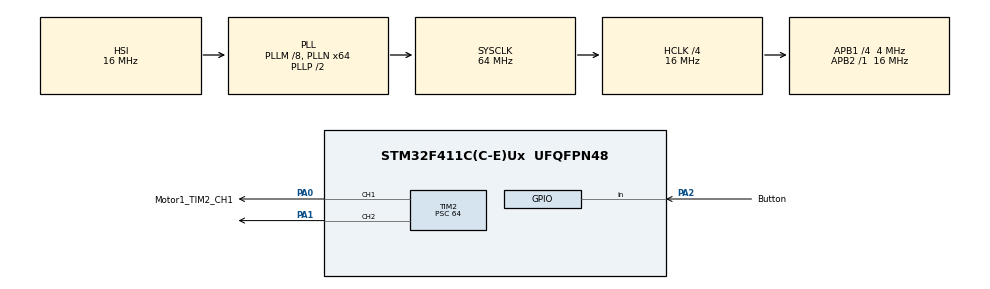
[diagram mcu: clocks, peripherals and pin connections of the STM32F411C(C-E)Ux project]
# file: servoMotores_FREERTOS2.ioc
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FREERTOS.Tasks01=gripperTask,26,128,StartGripperTask,Default,NULL,Dynamic,NULL,NULL;artTask,25,128,StartArtTask,Default,NULL,Dynamic,NULL,NULL;stopMotors,24,128,StopMotorMov,Default,NULL,Dynamic,NULL,NULL;receiveJetson,48,128,StartReceiveJetson,Default,NULL,Dynamic,NULL,NULL;emStop,32,128,StartEmStop,Default,NULL,Dynamic,NULL,NULL;checkButton,16,128,StartCheckButton,Default,NULL,Dynamic,NULL,NULL;transmitJetson,8,128,StartTransmitJEtson,Default,NULL,Dynamic,NULL,NULL
FREERTOS.configUSE_NEWLIB_REENTRANT=1
Mcu.Family=STM32F4
Mcu.Name=STM32F411C(C-E)Ux
Mcu.Package=UFQFPN48
NVIC.PriorityGroup=NVIC_PRIORITYGROUP_4
NVIC.TIM2_IRQn=true\:5\:0\:false\:false\:true\:true\:true\:true\:true
NVIC.TIM3_IRQn=true\:15\:0\:false\:false\:true\:false\:false\:true\:true
NVIC.TimeBase=TIM3_IRQn
NVIC.TimeBaseIP=TIM3
PA0-WKUP.GPIO_Label=Motor1_TIM2_CH1
PA0-WKUP.Signal=S_TIM2_CH1_ETR
PA1.Signal=S_TIM2_CH2
PA13.Mode=Serial_Wire
PA13.Signal=SYS_JTMS-SWDIO
PA14.Mode=Serial_Wire
PA14.Signal=SYS_JTCK-SWCLK
PA2.GPIO_Label=Button
PA2.Signal=GPIO_Input
PC14-OSC32_IN.Mode=LSE-External-Oscillator
PC14-OSC32_IN.Signal=RCC_OSC32_IN
PC15-OSC32_OUT.Mode=LSE-External-Oscillator
PC15-OSC32_OUT.Signal=RCC_OSC32_OUT
PH0\ -\ OSC_IN.Mode=HSE-External-Oscillator
PH0\ -\ OSC_IN.Signal=RCC_OSC_IN
PH1\ -\ OSC_OUT.Mode=HSE-External-Oscillator
PH1\ -\ OSC_OUT.Signal=RCC_OSC_OUT
ProjectManager.HeapSize=0x200
ProjectManager.StackSize=0x400
ProjectManager.TargetToolchain=STM32CubeIDE
RCC.48MHZClocksFreq_Value=32000000
RCC.AHBCLKDivider=RCC_SYSCLK_DIV4
RCC.AHBFreq_Value=16000000
RCC.APB1CLKDivider=RCC_HCLK_DIV4
RCC.APB1Freq_Value=4000000
RCC.APB1TimFreq_Value=8000000
RCC.APB2Freq_Value=16000000
RCC.APB2TimFreq_Value=16000000
RCC.CortexFreq_Value=16000000
RCC.HCLKFreq_Value=16000000
RCC.HSE_VALUE=25000000
RCC.HSI_VALUE=16000000
RCC.PLLM=8
RCC.PLLN=64
RCC.SYSCLKFreq_VALUE=64000000
RCC.SYSCLKSource=RCC_SYSCLKSOURCE_PLLCLK
RCC.VCOOutputFreq_Value=128000000
SH.S_TIM2_CH1_ETR.0=TIM2_CH1,PWM Generation1 CH1
SH.S_TIM2_CH2.0=TIM2_CH2,PWM Generation2 CH2
TIM2.Channel-PWM\ Generation1\ CH1=TIM_CHANNEL_1
TIM2.Channel-PWM\ Generation2\ CH2=TIM_CHANNEL_2
TIM2.Period=2499
TIM2.Prescaler=64
VP_FREERTOS_VS_CMSIS_V2.Mode=CMSIS_V2
VP_SYS_VS_tim3.Mode=TIM3
VP_TIM2_VS_ClockSourceINT.Mode=Internal
board=custom

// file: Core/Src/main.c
/* USER CODE BEGIN Header */
/**
  ******************************************************************************
  * @file           : main.c
  * @brief          : Main program body
  ******************************************************************************
  * @attention
  *
  * Copyright (c) 2023 STMicroelectronics.
  * All rights reserved.
  *
  * This software is licensed under terms that can be found in the LICENSE file
  * in the root directory of this software component.
  * If no LICENSE file comes with this software, it is provided AS-IS.
  *
  ******************************************************************************
  */
/* USER CODE END Header */
#include "main.h"
#include "cmsis_os.h"

TIM_HandleTypeDef htim2;

/* Definitions for gripperTask */
osThreadId_t gripperTaskHandle;
const osThreadAttr_t gripperTask_attributes = {
  .name = "gripperTask",
  .stack_size = 128 * 4,
  .priority = (osPriority_t) osPriorityNormal2,
};
/* Definitions for artTask */
osThreadId_t artTaskHandle;
const osThreadAttr_t artTask_attributes = {
  .name = "artTask",
  .stack_size = 128 * 4,
  .priority = (osPriority_t) osPriorityNormal1,
};
/* Definitions for stopMotors */
osThreadId_t stopMotorsHandle;
const osThreadAttr_t stopMotors_attributes = {
  .name = "stopMotors",
  .stack_size = 128 * 4,
  .priority = (osPriority_t) osPriorityNormal,
};
/* Definitions for receiveJetson */
osThreadId_t receiveJetsonHandle;
const osThreadAttr_t receiveJetson_attributes = {
  .name = "receiveJetson",
  .stack_size = 128 * 4,
  .priority = (osPriority_t) osPriorityRealtime,
};
/* Definitions for emStop */
osThreadId_t emStopHandle;
const osThreadAttr_t emStop_attributes = {
  .name = "emStop",
  .stack_size = 128 * 4,
  .priority = (osPriority_t) osPriorityAboveNormal,
};
/* Definitions for checkButton */
osThreadId_t checkButtonHandle;
const osThreadAttr_t checkButton_attributes = {
  .name = "checkButton",
  .stack_size = 128 * 4,
  .priority = (osPriority_t) osPriorityBelowNormal,
};
/* Definitions for transmitJetson */
osThreadId_t transmitJetsonHandle;
const osThreadAttr_t transmitJetson_attributes = {
  .name = "transmitJetson",
  .stack_size = 128 * 4,
  .priority = (osPriority_t) osPriorityLow,
};
/* USER CODE BEGIN PV */
int gripper = 0, art = 0;
int gripperOpen = 75, gripperClose = 127, artUp = 197, artDown = 83;
int comm[2];
int gripperFlag = 0, artFlag = 0, stopFlag = 0;
int gripperOK = 0, artOK = 0, stopOK = 0, objectHeld = 0;
int okFlags[4];
/* USER CODE END PV */

void SystemClock_Config(void);
static void MX_GPIO_Init(void);
static void MX_TIM2_Init(void);
void StartGripperTask(void *argument);
void StartArtTask(void *argument);
void StopMotorMov(void *argument);
void StartReceiveJetson(void *argument);
void StartEmStop(void *argument);
void StartCheckButton(void *argument);
void StartTransmitJEtson(void *argument);

/* USER CODE BEGIN PFP */
void read(void);
/* USER CODE END PFP */

int main(void)
{

  /* MCU Configuration--------------------------------------------------------*/

  /* Reset of all peripherals, Initializes the Flash interface and the Systick. */
  HAL_Init();

  /* Configure the system clock */
  SystemClock_Config();

  /* Initialize all configured peripherals */
  MX_GPIO_Init();
  MX_TIM2_Init();
  /* USER CODE BEGIN 2 */

  HAL_TIM_PWM_Start(&htim2,TIM_CHANNEL_1);
  HAL_TIM_PWM_Start(&htim2,TIM_CHANNEL_2);
  /* USER CODE END 2 */

  /* Init scheduler */
  osKernelInitialize();

  /* Create the thread(s) */
  /* creation of gripperTask */
  gripperTaskHandle = osThreadNew(StartGripperTask, NULL, &gripperTask_attributes);

  /* creation of artTask */
  artTaskHandle = osThreadNew(StartArtTask, NULL, &artTask_attributes);

  /* creation of stopMotors */
  stopMotorsHandle = osThreadNew(StopMotorMov, NULL, &stopMotors_attributes);

  /* creation of receiveJetson */
  receiveJetsonHandle = osThreadNew(StartReceiveJetson, NULL, &receiveJetson_attributes);

  /* creation of emStop */
  emStopHandle = osThreadNew(StartEmStop, NULL, &emStop_attributes);

  /* creation of checkButton */
  checkButtonHandle = osThreadNew(StartCheckButton, NULL, &checkButton_attributes);

  /* creation of transmitJetson */
  transmitJetsonHandle = osThreadNew(StartTransmitJEtson, NULL, &transmitJetson_attributes);

  /* Start scheduler */
  osKernelStart();
  /* We should never get here as control is now taken by the scheduler */
  /* Infinite loop */
  while (1)
  {

  }
}

void SystemClock_Config(void)
{
  RCC_OscInitTypeDef RCC_OscInitStruct = {0};
  RCC_ClkInitTypeDef RCC_ClkInitStruct = {0};

  /** Configure the main internal regulator output voltage
  */
  __HAL_RCC_PWR_CLK_ENABLE();
  __HAL_PWR_VOLTAGESCALING_CONFIG(PWR_REGULATOR_VOLTAGE_SCALE1);

  /** Initializes the RCC Oscillators according to the specified parameters
  * in the RCC_OscInitTypeDef structure.
  */
  RCC_OscInitStruct.OscillatorType = RCC_OSCILLATORTYPE_HSI;
  RCC_OscInitStruct.HSIState = RCC_HSI_ON;
  RCC_OscInitStruct.HSICalibrationValue = RCC_HSICALIBRATION_DEFAULT;
  RCC_OscInitStruct.PLL.PLLState = RCC_PLL_ON;
  RCC_OscInitStruct.PLL.PLLSource = RCC_PLLSOURCE_HSI;
  RCC_OscInitStruct.PLL.PLLM = 8;
  RCC_OscInitStruct.PLL.PLLN = 64;
  RCC_OscInitStruct.PLL.PLLP = RCC_PLLP_DIV2;
  RCC_OscInitStruct.PLL.PLLQ = 4;
  if (HAL_RCC_OscConfig(&RCC_OscInitStruct) != HAL_OK)
  {
    Error_Handler();
  }

  /** Initializes the CPU, AHB and APB buses clocks
  */
  RCC_ClkInitStruct.ClockType = RCC_CLOCKTYPE_HCLK|RCC_CLOCKTYPE_SYSCLK
                              |RCC_CLOCKTYPE_PCLK1|RCC_CLOCKTYPE_PCLK2;
  RCC_ClkInitStruct.SYSCLKSource = RCC_SYSCLKSOURCE_PLLCLK;
  RCC_ClkInitStruct.AHBCLKDivider = RCC_SYSCLK_DIV4;
  RCC_ClkInitStruct.APB1CLKDivider = RCC_HCLK_DIV4;
  RCC_ClkInitStruct.APB2CLKDivider = RCC_HCLK_DIV1;

  if (HAL_RCC_ClockConfig(&RCC_ClkInitStruct, FLASH_LATENCY_0) != HAL_OK)
  {
    Error_Handler();
  }
}

static void MX_TIM2_Init(void)
{

  TIM_ClockConfigTypeDef sClockSourceConfig = {0};
  TIM_MasterConfigTypeDef sMasterConfig = {0};
  TIM_OC_InitTypeDef sConfigOC = {0};

  htim2.Instance = TIM2;
  htim2.Init.Prescaler = 64;
  htim2.Init.CounterMode = TIM_COUNTERMODE_UP;
  htim2.Init.Period = 2499;
  htim2.Init.ClockDivision = TIM_CLOCKDIVISION_DIV1;
  htim2.Init.AutoReloadPreload = TIM_AUTORELOAD_PRELOAD_DISABLE;
  if (HAL_TIM_Base_Init(&htim2) != HAL_OK)
  {
    Error_Handler();
  }
  sClockSourceConfig.ClockSource = TIM_CLOCKSOURCE_INTERNAL;
  if (HAL_TIM_ConfigClockSource(&htim2, &sClockSourceConfig) != HAL_OK)
  {
    Error_Handler();
  }
  if (HAL_TIM_PWM_Init(&htim2) != HAL_OK)
  {
    Error_Handler();
  }
  sMasterConfig.MasterOutputTrigger = TIM_TRGO_RESET;
  sMasterConfig.MasterSlaveMode = TIM_MASTERSLAVEMODE_DISABLE;
  if (HAL_TIMEx_MasterConfigSynchronization(&htim2, &sMasterConfig) != HAL_OK)
  {
    Error_Handler();
  }
  sConfigOC.OCMode = TIM_OCMODE_PWM1;
  sConfigOC.Pulse = 0;
  sConfigOC.OCPolarity = TIM_OCPOLARITY_HIGH;
  sConfigOC.OCFastMode = TIM_OCFAST_DISABLE;
  if (HAL_TIM_PWM_ConfigChannel(&htim2, &sConfigOC, TIM_CHANNEL_1) != HAL_OK)
  {
    Error_Handler();
  }
  if (HAL_TIM_PWM_ConfigChannel(&htim2, &sConfigOC, TIM_CHANNEL_2) != HAL_OK)
  {
    Error_Handler();
  }
  HAL_TIM_MspPostInit(&htim2);

}

static void MX_GPIO_Init(void)
{
  GPIO_InitTypeDef GPIO_InitStruct = {0};

  /* GPIO Ports Clock Enable */
  __HAL_RCC_GPIOC_CLK_ENABLE();
  __HAL_RCC_GPIOH_CLK_ENABLE();
  __HAL_RCC_GPIOA_CLK_ENABLE();

  /*Configure GPIO pin : Button_Pin */
  GPIO_InitStruct.Pin = Button_Pin;
  GPIO_InitStruct.Mode = GPIO_MODE_INPUT;
  GPIO_InitStruct.Pull = GPIO_NOPULL;
  HAL_GPIO_Init(Button_GPIO_Port, &GPIO_InitStruct);

}

/* USER CODE BEGIN 4 */
void read() {
    comm[0] = 1;
    comm[1] = 2;
}
/* USER CODE END 4 */

void StartGripperTask(void *argument)
{
  /* USER CODE BEGIN 5 */
  /* Infinite loop */
  for(;;)
  {
	  if(gripperFlag == 1)
	  {
		  TIM2->CCR1 = gripperOpen;
		  osDelay(50);
		  gripperFlag = 0;
  		  gripperOK = 1;
	  }
	  else if (gripperFlag == 2)
	  {
		  TIM2->CCR1 = gripperClose;
		  osDelay(2000);
		  gripperFlag = 0;
  		  gripperOK = 1;
	  }
    osDelay(100);
  }
  /* USER CODE END 5 */
}

void StartArtTask(void *argument)
{
  /* USER CODE BEGIN StartArtTask */
  /* Infinite loop */
  for(;;)
  {
	  if(artFlag == 1)
	  	  {
	  		  TIM2->CCR2 = artUp;
	  		  osDelay(50);
	  		  artFlag = 0;
	  		  artOK = 1;
	  	  }
	 else if (artFlag == 2)
	  	  {
	  		  TIM2->CCR2 = artDown;
	  		  osDelay(50);
	  		  artFlag = 0;
	  		  artOK = 1;
	  	  }
	 osDelay(1);
  }
  /* USER CODE END StartArtTask */
}

void StopMotorMov(void *argument)
{
  for(;;)
  {
    osDelay(1);
  }
}

void StartReceiveJetson(void *argument)
{
  /* USER CODE BEGIN StartReceiveJetson */
  /* Infinite loop */
  for(;;)
  {
	 read();
	 switch (comm[0]){
	 	 case 1:
	 		 if (comm[1]==1)
				{
					gripperFlag = 1;
				}
			 else if (comm[1]==2)
				{
					gripperFlag = 2;
				}
			 else
				{
					gripperFlag = 0;
				}
			 break;
		 case 2:
			 if (comm[1]==1)
				{
					artFlag = 1;
				}
			 else if (comm[1]==2)
				{
					artFlag = 2;
				}
			 else
				{
					artFlag = 0;
				}
			 break;
		 case 3:
				stopFlag = 1;
				break;
		default:
				gripperFlag = 0;
				artFlag = 0;
				stopFlag = 0;
	            break;
		  }
	    osDelay(20000);
  }
  /* USER CODE END StartReceiveJetson */
}

void StartEmStop(void *argument)
{
  /* USER CODE BEGIN StartEmStop */
  /* Infinite loop */
  for(;;)
  {
	  if(stopFlag == 1){
		  gripperFlag = 0;
		  artFlag = 0;
		  stopFlag = 0;
	  }
    osDelay(1);
  }
  /* USER CODE END StartEmStop */
}

void StartCheckButton(void *argument)
{
  /* USER CODE BEGIN StartCheckButton */
  /* Infinite loop */
  for(;;)
  {
	  if(HAL_GPIO_ReadPin(GPIOA, GPIO_PIN_2) == GPIO_PIN_RESET){
	 		  objectHeld = 0;
	 	  }
	  else{
	 		  objectHeld = 1;
	 	  }
	  osDelay(1);
  }
  /* USER CODE END StartCheckButton */
}

void StartTransmitJEtson(void *argument)
{
  /* USER CODE BEGIN StartTransmitJEtson */
  /* Infinite loop */
  for(;;)
  {
	  if (gripperOK == 1)
	  {
		  okFlags[0]= gripperOK;
		  gripperOK = 0;
	  }
	  else
	  {
		  okFlags[0]= 0;
	  }
	  if (artOK == 1)
	  {
	  	  okFlags[1]= artOK;
	  	  artOK = 0;
	  }
	  else
	  {
		  okFlags[1]= 0;
	  }
	  if (objectHeld == 1)
	  {
	  	  okFlags[2]= objectHeld;
	  }
	  else
	  {
		  okFlags[2]= 0;
	  }
	  if (stopOK == 1)
	  {
	  	  okFlags[3]= stopOK;
	  	  stopOK = 0;
	  }
	  else
	  {
	  	  okFlags[3]= 0;
	  }
    osDelay(20100);
  }
  /* USER CODE END StartTransmitJEtson */
}

void HAL_TIM_PeriodElapsedCallback(TIM_HandleTypeDef *htim)
{
  if (htim->Instance == TIM3) {
    HAL_IncTick();
  }
}

void Error_Handler(void)
{
  __disable_irq();
  while (1)
  {
  }
}
